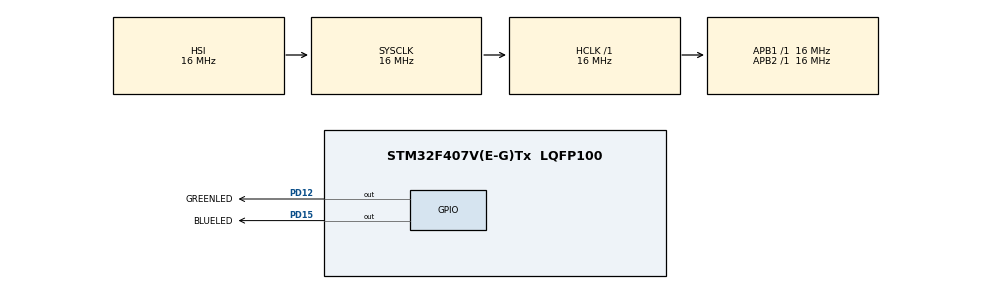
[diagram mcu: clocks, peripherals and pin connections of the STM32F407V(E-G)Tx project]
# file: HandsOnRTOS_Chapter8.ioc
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FREERTOS.BinarySemaphores01=semPtr,Static,SemPControlBlock
FREERTOS.Tasks01=defaultTask,24,128,StartDefaultTask,Default,NULL,Dynamic,NULL,NULL;GreenTask,8,128,StartGreenTask,Default,NULL,Static,GreenTaskBuffer,GreenTaskControlBlock;BlueTask,40,128,StartBlueTask,Default,NULL,Static,BlueTaskBuffer,BlueTaskControlBlock
Mcu.Family=STM32F4
Mcu.Name=STM32F407V(E-G)Tx
Mcu.Package=LQFP100
NVIC.PriorityGroup=NVIC_PRIORITYGROUP_4
NVIC.TIM7_IRQn=true\:0\:0\:false\:false\:true\:false\:false\:true
NVIC.TimeBase=TIM7_IRQn
NVIC.TimeBaseIP=TIM7
PD12.GPIO_Label=GREENLED
PD12.Signal=GPIO_Output
PD15.GPIO_Label=BLUELED
PD15.Signal=GPIO_Output
ProjectManager.HeapSize=0x200
ProjectManager.StackSize=0x400
ProjectManager.TargetToolchain=STM32CubeIDE
RCC.AHBFreq_Value=16000000
RCC.APB1Freq_Value=16000000
RCC.APB2Freq_Value=16000000
RCC.CortexFreq_Value=16000000
RCC.HSE_VALUE=25000000
RCC.HSI_VALUE=16000000
RCC.LSE_VALUE=32768
RCC.SYSCLKFreq_VALUE=16000000
RCC.VCOOutputFreq_Value=192000000
VP_FREERTOS_VS_CMSIS_V2.Mode=CMSIS_V2
VP_SYS_VS_tim7.Mode=TIM7
board=custom

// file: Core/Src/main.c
/* USER CODE BEGIN Header */
/**
  ******************************************************************************
  * @file           : main.c
  * @brief          : Main program body
  ******************************************************************************
  * @attention
  *
  * <h2><center>&copy; Copyright (c) 2020 STMicroelectronics.
  * All rights reserved.</center></h2>
  *
  * This software component is licensed by ST under BSD 3-Clause license,
  * the "License"; You may not use this file except in compliance with the
  * License. You may obtain a copy of the License at:
  *                        opensource.org/licenses/BSD-3-Clause
  *
  ******************************************************************************
  */
/* USER CODE END Header */
#include "main.h"
#include "cmsis_os.h"
#include "gpio.h"

/* USER CODE BEGIN Includes */
#include "SEGGER_SYSVIEW.h"
#include "SEGGER_RTT.h"
#include "SEGGER_SYSVIEW.h"
/* USER CODE END Includes */

void SystemClock_Config(void);
void MX_FREERTOS_Init(void);

int main(void)
{

  /* MCU Configuration--------------------------------------------------------*/

  /* Reset of all peripherals, Initializes the Flash interface and the Systick. */
  HAL_Init();

  /* USER CODE BEGIN Init */
  SEGGER_SYSVIEW_Conf();
  SEGGER_SYSVIEW_Start();
  /* USER CODE END Init */

  /* Configure the system clock */
  SystemClock_Config();

  /* Initialize all configured peripherals */
  MX_GPIO_Init();

  /* Init scheduler */
  osKernelInitialize();  /* Call init function for freertos objects (in freertos.c) */
  MX_FREERTOS_Init();
  /* Start scheduler */
  osKernelStart();

  /* We should never get here as control is now taken by the scheduler */
  /* Infinite loop */
  while (1)
  {

  }
}

void SystemClock_Config(void)
{
  RCC_OscInitTypeDef RCC_OscInitStruct = {0};
  RCC_ClkInitTypeDef RCC_ClkInitStruct = {0};

  /** Configure the main internal regulator output voltage
  */
  __HAL_RCC_PWR_CLK_ENABLE();
  __HAL_PWR_VOLTAGESCALING_CONFIG(PWR_REGULATOR_VOLTAGE_SCALE1);
  /** Initializes the RCC Oscillators according to the specified parameters
  * in the RCC_OscInitTypeDef structure.
  */
  RCC_OscInitStruct.OscillatorType = RCC_OSCILLATORTYPE_HSI;
  RCC_OscInitStruct.HSIState = RCC_HSI_ON;
  RCC_OscInitStruct.HSICalibrationValue = RCC_HSICALIBRATION_DEFAULT;
  RCC_OscInitStruct.PLL.PLLState = RCC_PLL_NONE;
  if (HAL_RCC_OscConfig(&RCC_OscInitStruct) != HAL_OK)
  {
    Error_Handler();
  }
  /** Initializes the CPU, AHB and APB buses clocks
  */
  RCC_ClkInitStruct.ClockType = RCC_CLOCKTYPE_HCLK|RCC_CLOCKTYPE_SYSCLK
                              |RCC_CLOCKTYPE_PCLK1|RCC_CLOCKTYPE_PCLK2;
  RCC_ClkInitStruct.SYSCLKSource = RCC_SYSCLKSOURCE_HSI;
  RCC_ClkInitStruct.AHBCLKDivider = RCC_SYSCLK_DIV1;
  RCC_ClkInitStruct.APB1CLKDivider = RCC_HCLK_DIV1;
  RCC_ClkInitStruct.APB2CLKDivider = RCC_HCLK_DIV1;

  if (HAL_RCC_ClockConfig(&RCC_ClkInitStruct, FLASH_LATENCY_0) != HAL_OK)
  {
    Error_Handler();
  }
}

void HAL_TIM_PeriodElapsedCallback(TIM_HandleTypeDef *htim)
{
  if (htim->Instance == TIM7) {
    HAL_IncTick();
  }
}

void Error_Handler(void)
{
}

/************************ (C) COPYRIGHT STMicroelectronics *****END OF FILE****/

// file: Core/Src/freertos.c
/* USER CODE BEGIN Header */
/**
  ******************************************************************************
  * File Name          : freertos.c
  * Description        : Code for freertos applications
  ******************************************************************************
  * @attention
  *
  * <h2><center>&copy; Copyright (c) 2020 STMicroelectronics.
  * All rights reserved.</center></h2>
  *
  * This software component is licensed by ST under Ultimate Liberty license
  * SLA0044, the "License"; You may not use this file except in compliance with
  * the License. You may obtain a copy of the License at:
  *                             www.st.com/SLA0044
  *
  ******************************************************************************
  */
/* USER CODE END Header */

#include "FreeRTOS.h"
#include "task.h"
#include "main.h"
#include "cmsis_os.h"

typedef StaticTask_t osStaticThreadDef_t;
typedef StaticSemaphore_t osStaticSemaphoreDef_t;

/* Definitions for defaultTask */
osThreadId_t defaultTaskHandle;
const osThreadAttr_t defaultTask_attributes = {
  .name = "defaultTask",
  .priority = (osPriority_t) osPriorityNormal,
  .stack_size = 128 * 4
};
/* Definitions for GreenTask */
osThreadId_t GreenTaskHandle;
uint32_t GreenTaskBuffer[ 128 ];
osStaticThreadDef_t GreenTaskControlBlock;
const osThreadAttr_t GreenTask_attributes = {
  .name = "GreenTask",
  .stack_mem = &GreenTaskBuffer[0],
  .stack_size = sizeof(GreenTaskBuffer),
  .cb_mem = &GreenTaskControlBlock,
  .cb_size = sizeof(GreenTaskControlBlock),
  .priority = (osPriority_t) osPriorityLow,
};
/* Definitions for BlueTask */
osThreadId_t BlueTaskHandle;
uint32_t BlueTaskBuffer[ 128 ];
osStaticThreadDef_t BlueTaskControlBlock;
const osThreadAttr_t BlueTask_attributes = {
  .name = "BlueTask",
  .stack_mem = &BlueTaskBuffer[0],
  .stack_size = sizeof(BlueTaskBuffer),
  .cb_mem = &BlueTaskControlBlock,
  .cb_size = sizeof(BlueTaskControlBlock),
  .priority = (osPriority_t) osPriorityHigh,
};
/* Definitions for semPtr */
osSemaphoreId_t semPtrHandle;
osStaticSemaphoreDef_t SemPControlBlock;
const osSemaphoreAttr_t semPtr_attributes = {
  .name = "semPtr",
  .cb_mem = &SemPControlBlock,
  .cb_size = sizeof(SemPControlBlock),
};

/* USER CODE BEGIN FunctionPrototypes */
void polledUartReceive(void * NotUsed){
	uint8_t nextbyte;
	while(1){
		while(!(USART2->SR & USART_SR_RXNE_Msk));
		nextbyte = USART2->DR;
		xQueueSend(uart2_BytesReceivedHandle,&nextbyte,0);
	}
}

void uartPrintOutTask(void *Notused){
	char nextByte;
	while(1){
		xQueueReceive(uart2_BytesReceivedHandle,&nextByte, 5000);
		SEGGER_SYSVIEW_PrintfHost("%c",nextByte);
	}
}
/* USER CODE END FunctionPrototypes */

void StartDefaultTask(void *argument);
void StartGreenTask(void *argument);
void StartBlueTask(void *argument);

void MX_FREERTOS_Init(void); /* (MISRA C 2004 rule 8.1) */

void MX_FREERTOS_Init(void) {

  /* Create the semaphores(s) */
  /* creation of semPtr */
  semPtrHandle = osSemaphoreNew(1, 1, &semPtr_attributes);

  /* Create the thread(s) */
  /* creation of defaultTask */
  defaultTaskHandle = osThreadNew(StartDefaultTask, NULL, &defaultTask_attributes);

  /* creation of GreenTask */
  GreenTaskHandle = osThreadNew(StartGreenTask, NULL, &GreenTask_attributes);

  /* creation of BlueTask */
  BlueTaskHandle = osThreadNew(StartBlueTask, NULL, &BlueTask_attributes);

}

void StartDefaultTask(void *argument)
{
  for(;;)
  {
    osDelay(1);
  }
}

void StartGreenTask(void *argument)
{
  /* USER CODE BEGIN StartGreenTask */
  int8_t countv =0;
  /* Infinite loop */
  for(;;)
  {
	 if(countv++ >= 5){
		 countv = 0;
		 SEGGER_SYSVIEW_PrintfHost("Task A (green LED) gives semPtr");
		 osSemaphoreRelease(semPtrHandle);

	 }
	 HAL_GPIO_WritePin(GREENLED_GPIO_Port,GREENLED_Pin,SET);
	 vTaskDelay(100);
	 HAL_GPIO_WritePin(GREENLED_GPIO_Port,GREENLED_Pin,RESET);
	 vTaskDelay(100);
  }
  /* USER CODE END StartGreenTask */
}

void StartBlueTask(void *argument)
{
  /* USER CODE BEGIN StartBlueTask */
	SEGGER_SYSVIEW_PrintfHost("Blue Task waiting for Semaphore");
  int8_t i;
  /* Infinite loop */
  for(;;)
  {
      if(osSemaphoreAcquire(semPtrHandle,1000) == osOK){
    	  for(i=0; i <3 ; i++){

    		 HAL_GPIO_WritePin(BLUELED_GPIO_Port,BLUELED_Pin,SET);
			 vTaskDelay(50);
			 HAL_GPIO_WritePin(BLUELED_GPIO_Port,BLUELED_Pin,RESET);
			 vTaskDelay(50);

    	  }
      }else {
		  //Timeout due to waiting for semaphore
    	  SEGGER_SYSVIEW_PrintfHost("Timeout Due to No Semaphore");
	  }
  }
  /* USER CODE END StartBlueTask */
}

/************************ (C) COPYRIGHT STMicroelectronics *****END OF FILE****/
